# ATSAM3U4C register map
Vendor: Atmel; File version: 0
CPU: CM3 r2p0, selectable endian, no MPU, no FPU, 0x4 interrupt priority bits, 0x0 interrupts
Registers are 32-bit, read-write, no defined reset value unless marked. A register's access mark holds for its fields unless they carry their own. Offsets are from the block's base; [hi:lo] are bit positions.

## RTC — Real-time Clock
Base 0x400E1260; register names take the prefix RTC_
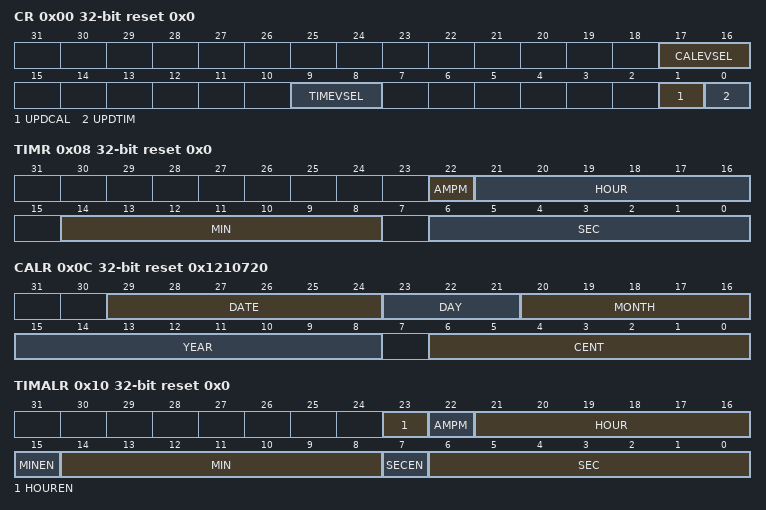
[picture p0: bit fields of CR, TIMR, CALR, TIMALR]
0x00 CR reset 0x0 — Control Register
  [17:16] CALEVSEL — Calendar Event Selection
    0=WEEK (Week change (every Monday at time 00:00:00)); 1=MONTH (Month change (every 01 of each month at time 00:00:00)); 2=YEAR (Year change (every January 1 at time 00:00:00))
  [9:8] TIMEVSEL — Time Event Selection
    0=MINUTE (Minute change); 1=HOUR (Hour change); 2=MIDNIGHT (Every day at midnight); 3=NOON (Every day at noon)
  [1] UPDCAL — Update Request Calendar Register
  [0] UPDTIM — Update Request Time Register
0x04 MR reset 0x0 — Mode Register
  [0] HRMOD — 12-/24-hour Mode
0x08 TIMR reset 0x0 — Time Register
  [22] AMPM — Ante Meridiem Post Meridiem Indicator
  [21:16] HOUR — Current Hour
  [14:8] MIN — Current Minute
  [6:0] SEC — Current Second
0x0C CALR reset 0x1210720 — Calendar Register
  [29:24] DATE — Current Day in Current Month
  [23:21] DAY — Current Day in Current Week
  [20:16] MONTH — Current Month
  [15:8] YEAR — Current Year
  [6:0] CENT — Current Century
0x10 TIMALR reset 0x0 — Time Alarm Register
  [23] HOUREN — Hour Alarm Enable
  [22] AMPM — AM/PM Indicator
  [21:16] HOUR — Hour Alarm
  [15] MINEN — Minute Alarm Enable
  [14:8] MIN — Minute Alarm
  [7] SECEN — Second Alarm Enable
  [6:0] SEC — Second Alarm
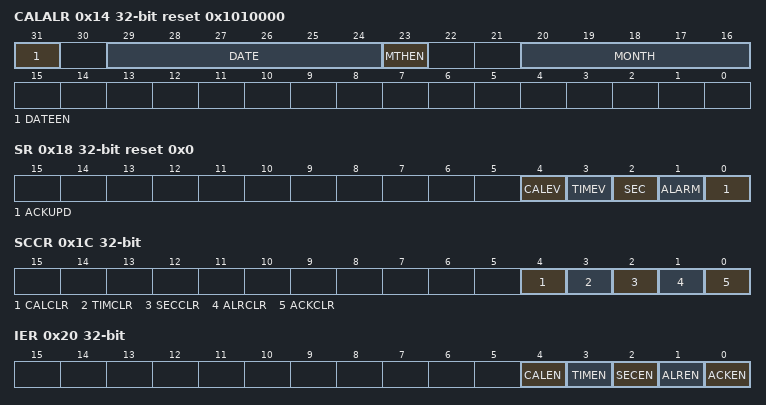
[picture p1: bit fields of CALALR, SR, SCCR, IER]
0x14 CALALR reset 0x1010000 — Calendar Alarm Register
  [31] DATEEN — Date Alarm Enable
  [29:24] DATE — Date Alarm
  [23] MTHEN — Month Alarm Enable
  [20:16] MONTH — Month Alarm
0x18 SR ro reset 0x0 — Status Register
  [4] CALEV — Calendar Event
    0=NO_CALEVENT (No calendar event has occurred since the last clear.); 1=CALEVENT (At least one calendar event has occurred since the last clear.)
  [3] TIMEV — Time Event
    0=NO_TIMEVENT (No time event has occurred since the last clear.); 1=TIMEVENT (At least one time event has occurred since the last clear.)
  [2] SEC — Second Event
    0=NO_SECEVENT (No second event has occurred since the last clear.); 1=SECEVENT (At least one second event has occurred since the last clear.)
  [1] ALARM — Alarm Flag
    0=NO_ALARMEVENT (No alarm matching condition occurred.); 1=ALARMEVENT (An alarm matching condition has occurred.)
  [0] ACKUPD — Acknowledge for Update
    0=FREERUN (Time and calendar registers cannot be updated.); 1=UPDATE (Time and calendar registers can be updated.)
0x1C SCCR wo — Status Clear Command Register
  [4] CALCLR — Calendar Clear
  [3] TIMCLR — Time Clear
  [2] SECCLR — Second Clear
  [1] ALRCLR — Alarm Clear
  [0] ACKCLR — Acknowledge Clear
0x20 IER wo — Interrupt Enable Register
  [4] CALEN — Calendar Event Interrupt Enable
  [3] TIMEN — Time Event Interrupt Enable
  [2] SECEN — Second Event Interrupt Enable
  [1] ALREN — Alarm Interrupt Enable
  [0] ACKEN — Acknowledge Update Interrupt Enable
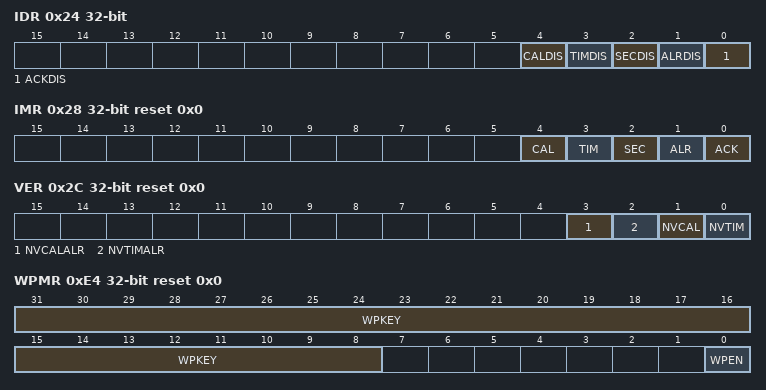
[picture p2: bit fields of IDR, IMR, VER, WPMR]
0x24 IDR wo — Interrupt Disable Register
  [4] CALDIS — Calendar Event Interrupt Disable
  [3] TIMDIS — Time Event Interrupt Disable
  [2] SECDIS — Second Event Interrupt Disable
  [1] ALRDIS — Alarm Interrupt Disable
  [0] ACKDIS — Acknowledge Update Interrupt Disable
0x28 IMR ro reset 0x0 — Interrupt Mask Register
  [4] CAL — Calendar Event Interrupt Mask
  [3] TIM — Time Event Interrupt Mask
  [2] SEC — Second Event Interrupt Mask
  [1] ALR — Alarm Interrupt Mask
  [0] ACK — Acknowledge Update Interrupt Mask
0x2C VER ro reset 0x0 — Valid Entry Register
  [3] NVCALALR — Non-valid Calendar Alarm
  [2] NVTIMALR — Non-valid Time Alarm
  [1] NVCAL — Non-valid Calendar
  [0] NVTIM — Non-valid Time
0xE4 WPMR reset 0x0 — Write Protect Mode Register
  [31:8] WPKEY — Write Protect KEY
    0x525443=PASSWD (Writing any other value in this field aborts the write operation of the WPEN bit.Always reads as 0.)
  [0] WPEN — Write Protect Enable
